# LM3S828 register map
File version: 7944
Registers are 32-bit, read-write, no defined reset value unless marked. A register's access mark holds for its fields unless they carry their own. Offsets are from the block's base; [hi:lo] are bit positions; <NAME> marks a mode.

## UART0 — Register map for UART0 peripheral
Base 0x4000C000; register names take the prefix UART0
Same registers: UART1 0x4000D000 (register names take the prefix UART1)
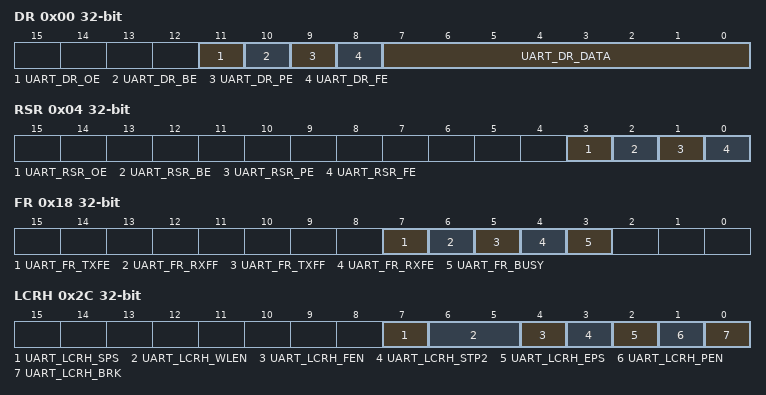
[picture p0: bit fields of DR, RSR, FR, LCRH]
0x00 DR — UART Data
  [11] UART_DR_OE — UART Overrun Error
  [10] UART_DR_BE — UART Break Error
  [9] UART_DR_PE — UART Parity Error
  [8] UART_DR_FE — UART Framing Error
  [7:0] UART_DR_DATA — Data Transmitted or Received
0x04 RSR — UART Receive Status/Error Clear
  [3] UART_RSR_OE — UART Overrun Error
  [2] UART_RSR_BE — UART Break Error
  [1] UART_RSR_PE — UART Parity Error
  [0] UART_RSR_FE — UART Framing Error
0x04 ECR (UART_ALT view) — UART Receive Status/Error Clear
  [7:0] UART_ECR_DATA — Error Clear
0x18 FR — UART Flag
  [7] UART_FR_TXFE — UART Transmit FIFO Empty
  [6] UART_FR_RXFF — UART Receive FIFO Full
  [5] UART_FR_TXFF — UART Transmit FIFO Full
  [4] UART_FR_RXFE — UART Receive FIFO Empty
  [3] UART_FR_BUSY — UART Busy
0x24 IBRD — UART Integer Baud-Rate Divisor
  [15:0] UART_IBRD_DIVINT — Integer Baud-Rate Divisor
0x28 FBRD — UART Fractional Baud-Rate Divisor
  [5:0] UART_FBRD_DIVFRAC — Fractional Baud-Rate Divisor
0x2C LCRH — UART Line Control
  [7] UART_LCRH_SPS — UART Stick Parity Select
  [6:5] UART_LCRH_WLEN — UART Word Length
    0=5 bits (default); 1=6 bits; 2=7 bits; 3=8 bits
  [4] UART_LCRH_FEN — UART Enable FIFOs
  [3] UART_LCRH_STP2 — UART Two Stop Bits Select
  [2] UART_LCRH_EPS — UART Even Parity Select
  [1] UART_LCRH_PEN — UART Parity Enable
  [0] UART_LCRH_BRK — UART Send Break
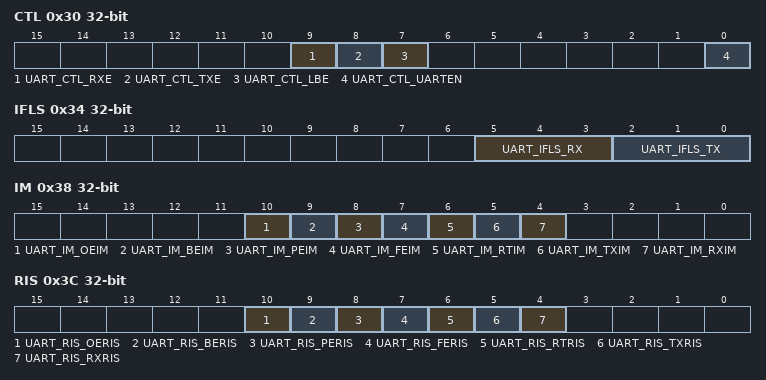
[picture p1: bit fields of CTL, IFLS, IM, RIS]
0x30 CTL — UART Control
  [9] UART_CTL_RXE — UART Receive Enable
  [8] UART_CTL_TXE — UART Transmit Enable
  [7] UART_CTL_LBE — UART Loop Back Enable
  [0] UART_CTL_UARTEN — UART Enable
0x34 IFLS — UART Interrupt FIFO Level Select
  [5:3] UART_IFLS_RX — UART Receive Interrupt FIFO Level Select
    0=UART_IFLS_RX1_8 (RX FIFO >= 1/8 full); 1=UART_IFLS_RX2_8 (RX FIFO >= 1/4 full); 2=UART_IFLS_RX4_8 (RX FIFO >= 1/2 full (default)); 3=UART_IFLS_RX6_8 (RX FIFO >= 3/4 full); 4=UART_IFLS_RX7_8 (RX FIFO >= 7/8 full)
  [2:0] UART_IFLS_TX — UART Transmit Interrupt FIFO Level Select
    0=UART_IFLS_TX1_8 (TX FIFO <= 1/8 full); 1=UART_IFLS_TX2_8 (TX FIFO <= 1/4 full); 2=UART_IFLS_TX4_8 (TX FIFO <= 1/2 full (default)); 3=UART_IFLS_TX6_8 (TX FIFO <= 3/4 full); 4=UART_IFLS_TX7_8 (TX FIFO <= 7/8 full)
0x38 IM — UART Interrupt Mask
  [10] UART_IM_OEIM — UART Overrun Error Interrupt Mask
  [9] UART_IM_BEIM — UART Break Error Interrupt Mask
  [8] UART_IM_PEIM — UART Parity Error Interrupt Mask
  [7] UART_IM_FEIM — UART Framing Error Interrupt Mask
  [6] UART_IM_RTIM — UART Receive Time-Out Interrupt Mask
  [5] UART_IM_TXIM — UART Transmit Interrupt Mask
  [4] UART_IM_RXIM — UART Receive Interrupt Mask
0x3C RIS — UART Raw Interrupt Status
  [10] UART_RIS_OERIS — UART Overrun Error Raw Interrupt Status
  [9] UART_RIS_BERIS — UART Break Error Raw Interrupt Status
  [8] UART_RIS_PERIS — UART Parity Error Raw Interrupt Status
  [7] UART_RIS_FERIS — UART Framing Error Raw Interrupt Status
  [6] UART_RIS_RTRIS — UART Receive Time-Out Raw Interrupt Status
  [5] UART_RIS_TXRIS — UART Transmit Raw Interrupt Status
  [4] UART_RIS_RXRIS — UART Receive Raw Interrupt Status
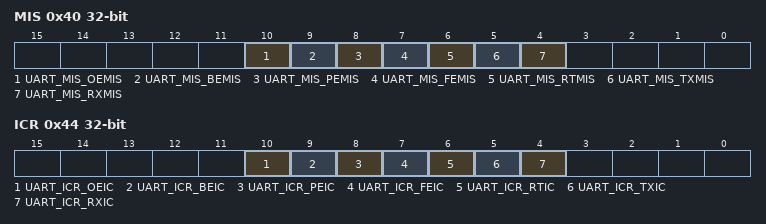
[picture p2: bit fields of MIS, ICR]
0x40 MIS — UART Masked Interrupt Status
  [10] UART_MIS_OEMIS — UART Overrun Error Masked Interrupt Status
  [9] UART_MIS_BEMIS — UART Break Error Masked Interrupt Status
  [8] UART_MIS_PEMIS — UART Parity Error Masked Interrupt Status
  [7] UART_MIS_FEMIS — UART Framing Error Masked Interrupt Status
  [6] UART_MIS_RTMIS — UART Receive Time-Out Masked Interrupt Status
  [5] UART_MIS_TXMIS — UART Transmit Masked Interrupt Status
  [4] UART_MIS_RXMIS — UART Receive Masked Interrupt Status
0x44 ICR wo — UART Interrupt Clear
  [10] UART_ICR_OEIC — Overrun Error Interrupt Clear
  [9] UART_ICR_BEIC — Break Error Interrupt Clear
  [8] UART_ICR_PEIC — Parity Error Interrupt Clear
  [7] UART_ICR_FEIC — Framing Error Interrupt Clear
  [6] UART_ICR_RTIC — Receive Time-Out Interrupt Clear
  [5] UART_ICR_TXIC — Transmit Interrupt Clear
  [4] UART_ICR_RXIC — Receive Interrupt Clear

## I2C0 — Register map for I2C0 peripheral
Base 0x40020000; register names take the prefix I2C0
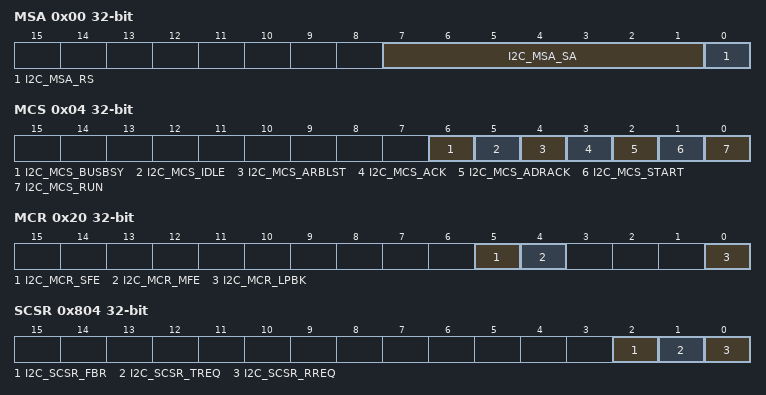
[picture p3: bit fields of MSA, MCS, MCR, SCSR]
0x00 MSA — I2C Master Slave Address
  [7:1] I2C_MSA_SA — I2C Slave Address
  [0] I2C_MSA_RS — Receive not send
0x04 MCS — I2C Master Control/Status
  [6] I2C_MCS_BUSBSY — Bus Busy
  [5] I2C_MCS_IDLE — I2C Idle
  [4] I2C_MCS_ARBLST — Arbitration Lost
  [3] I2C_MCS_ACK — Data Acknowledge Enable
  [2] I2C_MCS_ADRACK — Acknowledge Address
  [1] I2C_MCS_START — Generate START
  [0] I2C_MCS_RUN — I2C Master Enable
0x04 MCS (I2C0_ALT view) — I2C Master Control/Status
  [3] I2C_MCS_DATACK — Acknowledge Data
  [2] I2C_MCS_STOP — Generate STOP
  [1] I2C_MCS_ERROR — Error
  [0] I2C_MCS_BUSY — I2C Busy
0x08 MDR — I2C Master Data
  [7:0] I2C_MDR_DATA — Data Transferred
0x0C MTPR — I2C Master Timer Period
  [6:0] I2C_MTPR_TPR — SCL Clock Period
0x10 MIMR — I2C Master Interrupt Mask
  [0] I2C_MIMR_IM — Interrupt Mask
0x14 MRIS — I2C Master Raw Interrupt Status
  [0] I2C_MRIS_RIS — Raw Interrupt Status
0x18 MMIS — I2C Master Masked Interrupt Status
  [0] I2C_MMIS_MIS — Masked Interrupt Status
0x1C MICR wo — I2C Master Interrupt Clear
  [0] I2C_MICR_IC — Interrupt Clear
0x20 MCR — I2C Master Configuration
  [5] I2C_MCR_SFE — I2C Slave Function Enable
  [4] I2C_MCR_MFE — I2C Master Function Enable
  [0] I2C_MCR_LPBK — I2C Loopback
0x800 SOAR — I2C Slave Own Address
  [6:0] I2C_SOAR_OAR
0x804 SCSR — I2C Slave Control/Status
  [2] I2C_SCSR_FBR — First Byte Received
  [1] I2C_SCSR_TREQ — Transmit Request
  [0] I2C_SCSR_RREQ — Receive Request
0x804 SCSR (I2C0_ALT view) — I2C Slave Control/Status
  [0] I2C_SCSR_DA — Device Active
0x808 SDR — I2C Slave Data
  [7:0] I2C_SDR_DATA — Data for Transfer
0x80C SIMR — I2C Slave Interrupt Mask
  [0] I2C_SIMR_DATAIM — Data Interrupt Mask
0x810 SRIS — I2C Slave Raw Interrupt Status
  [0] I2C_SRIS_DATARIS — Data Raw Interrupt Status
0x814 SMIS — I2C Slave Masked Interrupt Status
  [0] I2C_SMIS_DATAMIS — Data Masked Interrupt Status
0x818 SICR wo — I2C Slave Interrupt Clear
  [0] I2C_SICR_DATAIC — Data Interrupt Clear

## FLASH_CTRL — Register map for FLASH_CTRL peripheral
Base 0x400FD000; register names take the prefix FLASH_CTRL
0x00 FMA — Flash Memory Address
  [15:0] FLASH_FMA_OFFSET — Address Offset
0x04 FMD — Flash Memory Data
  [31:0] FLASH_FMD_DATA — Data Value
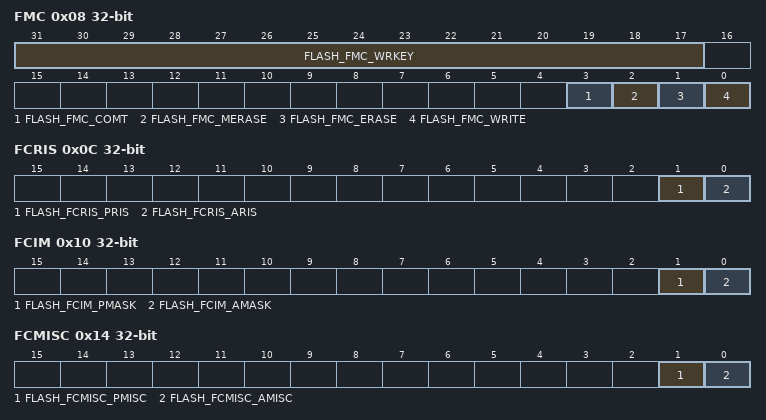
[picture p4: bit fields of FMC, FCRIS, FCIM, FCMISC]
0x08 FMC — Flash Memory Control
  [31:17] FLASH_FMC_WRKEY — FLASH write key
  [3] FLASH_FMC_COMT — Commit Register Value
  [2] FLASH_FMC_MERASE — Mass Erase Flash Memory
  [1] FLASH_FMC_ERASE — Erase a Page of Flash Memory
  [0] FLASH_FMC_WRITE — Write a Word into Flash Memory
0x0C FCRIS — Flash Controller Raw Interrupt Status
  [1] FLASH_FCRIS_PRIS — Programming Raw Interrupt Status
  [0] FLASH_FCRIS_ARIS — Access Raw Interrupt Status
0x10 FCIM — Flash Controller Interrupt Mask
  [1] FLASH_FCIM_PMASK — Programming Interrupt Mask
  [0] FLASH_FCIM_AMASK — Access Interrupt Mask
0x14 FCMISC — Flash Controller Masked Interrupt Status and Clear
  [1] FLASH_FCMISC_PMISC — Programming Masked Interrupt Status and Clear
  [0] FLASH_FCMISC_AMISC — Access Masked Interrupt Status and Clear
0x1130 FMPRE — Flash Memory Protection Read Enable
0x1134 FMPPE — Flash Memory Protection Program Enable
0x1140 USECRL — USec Reload
  [7:0] FLASH_USECRL — Microsecond Reload Value
